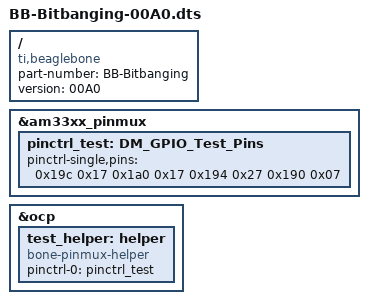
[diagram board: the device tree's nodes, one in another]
/dts-v1/;
/plugin/;

/{
	       compatible = "ti,beaglebone", "ti,beaglebone-black";
	       part-number = "BB-Bitbanging";
	       version = "00A0";
	       fragment@0 {
		       target = <&am33xx_pinmux>;						         
	     	       __overlay__ {

                        pinctrl_test: DM_GPIO_Test_Pins {
			pinctrl-single,pins = <
			      0x19c 0x17 /* P9_28  OUTPUT PULLUP MODE7 - CS0 */	
		              0x1a0 0x17 /* P9_42  OUTPUT PULLUP MODE7 - CS1 */
			      0x194 0x27 /* P9_29 INPUT MODE7 - D0 */
			      0x190 0x07 /* P9_31  INPUT MODE7 pullup - CLK */
      			      /* OUTPUT GPIO(mode7) 0x07 pulldown, 0x17 pullup, 0x?f no pullup/down */
     			      /* INPUT GPIO(mode7) 0x27 pulldown, 0x37 pullup, 0x?f no pullup/down */


						
					      >;
						  };
		       };
	       };

	       fragment@1 {
		       target = <&ocp>;
		       __overlay__ {
                     test_helper: helper {
		     compatible = "bone-pinmux-helper";
		     pinctrl-names = "default";
		     pinctrl-0 = <&pinctrl_test>;
		     status = "okay";
	     };
	
		       };
	       };
};
